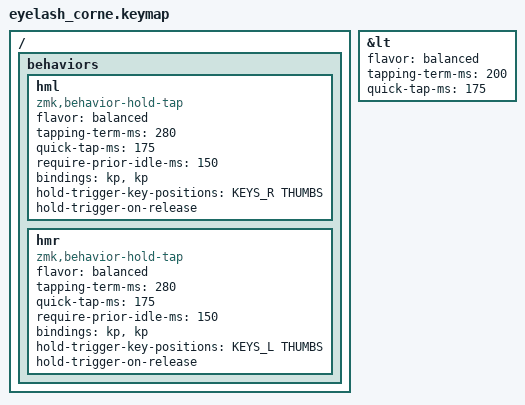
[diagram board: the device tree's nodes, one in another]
#include <behaviors.dtsi>
#include <dt-bindings/zmk/keys.h>

#include <dt-bindings/zmk/bt.h>
#include <dt-bindings/zmk/outputs.h>
#include <dt-bindings/zmk/ext_power.h>
#include <dt-bindings/zmk/rgb.h>

#include "zmk-helpers/helper.h"
#include "zmk-helpers/key-labels/eyelash42.h"

#include "mouse.dtsi"

// This keyboard layout is losely based on Miryoku.
// Todo:
// - [x] correct the number layer to include all numbers.
// - [x] add meny key.
// - [ ] correct navigation layer to put navigation symbols to right hand.
// - [ ] put the mouse navigation to joystick.
// - [ ] add the layers to configure bluetooth connections.


#define ZMK_BASE_LAYER(name, LT, RT, LM, RM, LB, RB, LH, RH, LS0, LS13, LS4, sensors)                   \
    ZMK_LAYER(                                                                 \
        name,                                                                  \
                 LT     LS0     RT                  \
                 LM     LS13    RM                  \
                 LB     LS4     RB                  \
                 LH             RH                  \
    ,sensors)


#define _BT_SEL_KEYS_                                                        \
    &bt BT_SEL 0 &bt BT_SEL 1 &bt BT_SEL 2 &bt BT_SEL 3 &bt BT_CLR

#define DEF 0
#define FN  1
#define NAV 2
#define SYM 3
#define CFG 4

#define XXX &none
#define ___ &trans

/* Global defaults */

/* Homerow mods */

#define KEYS_L LT0 LT1 LT2 LT3 LT4 LM0 LM1 LM2 LM3 LM4 LB0 LB1 LB2 LB3 LB4
#define KEYS_R RT0 RT1 RT2 RT3 RT4 RM0 RM1 RM2 RM3 RM4 RB0 RB1 RB2 RB3 RB4

#define THUMBS LH2 LH1 LH0 RH0 RH1 RH2 // Thumbs on 36+ keys.

#define U_COPY RC(INS)
#define U_PASTE RS(INS)
#define U_CUT RS(DEL)

#define U_UNDO RC(Z)
#define U_REDO LC(LA(Z))

#define U_TILDE RS(GRAVE)

&lt {
  flavor = "balanced";
  tapping-term-ms = <200>;
  quick-tap-ms = <175>;
};

/* Left-hand HRMs. */
ZMK_HOLD_TAP(hml,
    flavor = "balanced";
    tapping-term-ms = <280>;
    quick-tap-ms = <175>;
    require-prior-idle-ms = <150>;
    bindings = <&kp>, <&kp>;
    hold-trigger-key-positions = <KEYS_R THUMBS>;
    hold-trigger-on-release;
)

/* Right-hand HRMs. */
ZMK_HOLD_TAP(hmr,
    flavor = "balanced";
    tapping-term-ms = <280>;
    quick-tap-ms = <175>;
    require-prior-idle-ms = <150>;
    bindings = <&kp>, <&kp>;
    hold-trigger-key-positions = <KEYS_L THUMBS>;
    hold-trigger-on-release;
)


/* Keymap */

#define kBKSLASH NON_US_BACKSLASH


ZMK_BASE_LAYER(Qwerty,
// ╭───────────────┬───────────────┬───────────────┬───────────────┬───────────────┬───────────────╮          ╭───────────────┬───────────────┬───────────────┬───────────────┬───────────────┬───────────────╮
    &lt 4 GRAVE     &kp Q           &kp W           &kp E            &kp R          &kp T          ,           &kp Y           &kp U           &kp I           &kp O           &kp P           &lt 4 LEFT_BRACKET,
// ├───────────────┼───────────────┼───────────────┼───────────────┼───────────────┼───────────────┤          ├───────────────┼───────────────┼───────────────┼───────────────┼───────────────┼───────────────┤
    &kp kBKSLASH    &hml LGUI A     &hml LALT S     &hml LCTRL D    &hml LSHFT F   &kp G           ,           &kp H           &hmr RSHFT J    &hmr RCTRL K    &hmr LALT L     &hmr RGUI SEMI  &kp RIGHT_BRACKET,
// ├───────────────┼───────────────┼───────────────┼───────────────┼───────────────┼───────────────┤          ├───────────────┼───────────────┼───────────────┼───────────────┼───────────────┼───────────────┤
    &kp MINUS       &kp Z           &kp X           &kp C           &kp V           &kp B          ,           &kp N           &kp M           &kp COMMA       &kp DOT         &kp FSLH        &kp SQT        ,
// ╰───────────────┴───────────────┴───────────────┼───────────────┼───────────────┼───────────────┤          ├───────────────┼───────────────┼───────────────┼───────────────┴───────────────┴───────────────╯
                                                    &lt 1 ESCAPE    &lt 2 SPACE     &lt 3 TAB      ,           &lt 3 ENTER     &lt 2 BACKSPACE &lt 1  DELETE  ,
//                                                 ╰───────────────┴───────────────┴───────────────╯          ╰───────────────┴───────────────┴───────────────╯
// ╭───────────────┬───────────────┬───────────────╮
                     &kp UP                        ,
// ├───────────────┼───────────────┼───────────────┤
    &kp LEFT         &kp ENTER         &kp RIGHT   ,
// ├───────────────┼───────────────┼───────────────┤
    &kp C_MUTE       &kp DOWN                      ,
// ╰───────────────┴───────────────┴───────────────╯
&inc_dec_kp C_VOLUME_UP C_VOLUME_DOWN
)

ZMK_BASE_LAYER(Funnum,
// ╭───────────────┬───────────────┬───────────────┬───────────────┬───────────────┬───────────────╮          ╭───────────────┬───────────────┬───────────────┬───────────────┬───────────────┬───────────────╮
    XXX             &kp F9          &kp F10         &kp F11         &kp F12         &kp KP_MULTIPLY,           &kp PLUS        &kp N7          &kp N8          &kp N9          &kp N0          XXX            ,
// ├───────────────┼───────────────┼───────────────┼───────────────┼───────────────┼───────────────┤          ├───────────────┼───────────────┼───────────────┼───────────────┼───────────────┼───────────────┤
    XXX             &hml LGUI F5    &hml LALT F6    &hml LCTRL F7   &hml LSHFT F8   &kp KP_DIVIDE  ,           &kp MINUS       &hmr RSHFT N4   &hmr RCTRL N5   &hmr LALT N6    &kp  LGUI       XXX            ,
// ├───────────────┼───────────────┼───────────────┼───────────────┼───────────────┼───────────────┤          ├───────────────┼───────────────┼───────────────┼───────────────┼───────────────┼───────────────┤
    XXX             &kp F1          &kp F2          &kp F3          &kp F4          &kp kBKSLASH   ,           &kp EQUAL    &kp N1          &kp N2          &kp N3             XXX             XXX            ,
// ╰───────────────┴───────────────┴───────────────┼───────────────┼───────────────┼───────────────┤          ├───────────────┼───────────────┼───────────────┼───────────────┴───────────────┴───────────────╯
                                                    ___             ___             ___            ,           ___             ___             ___            ,
//                                                 ╰───────────────┴───────────────┴───────────────╯          ╰───────────────┴───────────────┴───────────────╯
// ╭───────────────┬───────────────┬───────────────╮
                     &kp UP                        ,
// ├───────────────┼───────────────┼───────────────┤
    &kp LEFT         &kp ENTER         &kp RIGHT   ,
// ├───────────────┼───────────────┼───────────────┤
    &kp B            &kp DOWN                      ,
// ╰───────────────┴───────────────┴───────────────╯
&inc_dec_kp C_VOLUME_UP C_VOLUME_DOWN
)

ZMK_BASE_LAYER(Nav,
// ╭───────────────┬───────────────┬───────────────┬───────────────┬───────────────┬───────────────╮          ╭───────────────┬───────────────┬───────────────┬───────────────┬───────────────┬───────────────╮
    XXX             &kp CAPS        &mkp LCLK       &mkp MCLK       &mkp RCLK       U_WH_U         ,           &kp PG_UP       &kp HOME        &kp UP          &kp END         &kp PSCRN       XXX            ,
// ├───────────────┼───────────────┼───────────────┼───────────────┼───────────────┼───────────────┤          ├───────────────┼───────────────┼───────────────┼───────────────┼───────────────┼───────────────┤
    XXX             &kp LGUI        &kp LALT        &kp LCTRL       &kp RSHFT       U_WH_D         ,           &kp PG_DN       &kp LEFT        &kp DOWN        &kp RIGHT       &kp PAUSE_BREAK XXX            ,
// ├───────────────┼───────────────┼───────────────┼───────────────┼───────────────┼───────────────┤          ├───────────────┼───────────────┼───────────────┼───────────────┼───────────────┼───────────────┤
    XXX             &kp U_UNDO      &kp U_CUT       &kp U_COPY      &kp U_PASTE     &kp K_APP      ,           &kp INS         XXX             XXX             XXX             XXX             XXX            ,
// ╰───────────────┴───────────────┴───────────────┼───────────────┼───────────────┼───────────────┤          ├───────────────┼───────────────┼───────────────┼───────────────┴───────────────┴───────────────╯
                                                    ___             ___             ___            ,           ___             ___             ___            ,
//                                                 ╰───────────────┴───────────────┴───────────────╯          ╰───────────────┴───────────────┴───────────────╯

// ╭───────────────┬───────────────┬───────────────╮
                    U_MS_U                         ,
// ├───────────────┼───────────────┼───────────────┤
    U_MS_L          &mkp LCLK       U_MS_R         ,
// ├───────────────┼───────────────┼───────────────┤
    &mkp RCLK       U_MS_D                         ,
// ╰───────────────┴───────────────┴───────────────╯
&inc_dec_kp C_VOLUME_UP C_VOLUME_DOWN
)

ZMK_BASE_LAYER(Symbol,
// ╭───────────────┬───────────────┬───────────────┬───────────────┬───────────────┬───────────────╮          ╭───────────────┬───────────────┬───────────────┬───────────────┬───────────────┬───────────────╮
    XXX             &kp LESS_THAN   &kp EXCL        &kp KP_MINUS    &kp GREATER_THAN &kp AMPERSAND ,           &kp CARET       &kp LEFT_BRACE  &kp RIGHT_BRACE &kp DOLLAR      &kp UNDERSCORE  XXX            ,
// ├───────────────┼───────────────┼───────────────┼───────────────┼───────────────┼───────────────┤          ├───────────────┼───────────────┼───────────────┼───────────────┼───────────────┼───────────────┤
    XXX             &hml LGUI LBKT  &hml LALT RBKT  &hml LCTRL KP_PLUS &hml LSHFT  EQUAL  &kp PIPE ,           &kp HASH        &hmr RSHFT LPAR &hmr RCTRL RPAR &hmr LALT SEMI  &hmr RGUI DOUBLE_QUOTES XXX    ,
// ├───────────────┼───────────────┼───────────────┼───────────────┼───────────────┼───────────────┤          ├───────────────┼───────────────┼───────────────┼───────────────┼───────────────┼───────────────┤
    XXX             &kp GRAVE       &kp TILDE       &kp KP_MULTIPLY &kp KP_DIVIDE   &kp PERCENT    ,           &kp AT          &kp COLON       &kp COMMA       &kp DOT         &kp APOSTROPHE  XXX            ,
// ╰───────────────┴───────────────┴───────────────┼───────────────┼───────────────┼───────────────┤          ├───────────────┼───────────────┼───────────────┼───────────────┴───────────────┴───────────────╯
                                                    ___             ___             ___            ,           ___             ___             ___            ,
//                                                 ╰───────────────┴───────────────┴───────────────╯          ╰───────────────┴───────────────┴───────────────╯

// ╭───────────────┬───────────────┬───────────────╮
                     &kp UP                        ,
// ├───────────────┼───────────────┼───────────────┤
    &kp LEFT         &kp ENTER      &kp RIGHT      ,
// ├───────────────┼───────────────┼───────────────┤
    &kp D            &kp DOWN                      ,
// ╰───────────────┴───────────────┴───────────────╯
&inc_dec_kp C_VOLUME_UP C_VOLUME_DOWN
)


ZMK_BASE_LAYER(Config,
// ╭───────────────┬───────────────┬───────────────┬───────────────┬───────────────┬───────────────╮          ╭───────────────┬───────────────┬───────────────┬───────────────┬───────────────┬───────────────╮
    ___             &bt BT_SEL 0    &bt BT_SEL 1    &bt BT_SEL 2    &bt BT_SEL 3    &bt BT_SEL 4   ,           &rgb_ug RGB_EFR ___             ___             ___             ___             ___            ,
// ├───────────────┼───────────────┼───────────────┼───────────────┼───────────────┼───────────────┤          ├───────────────┼───────────────┼───────────────┼───────────────┼───────────────┼───────────────┤
    ___             ___             ___             ___             ___             &out OUT_BLE   ,           &rgb_ug RGB_EFF ___             ___             ___             ___             ___            ,
// ├───────────────┼───────────────┼───────────────┼───────────────┼───────────────┼───────────────┤          ├───────────────┼───────────────┼───────────────┼───────────────┼───────────────┼───────────────┤
    ___             ___             ___             ___             ___             &out OUT_USB            ,           ___             ___             ___             ___             ___             ___            ,
// ╰───────────────┴───────────────┴───────────────┼───────────────┼───────────────┼───────────────┤          ├───────────────┼───────────────┼───────────────┼───────────────┴───────────────┴───────────────╯
                                                    ___             ___             ___            ,           ___             ___             ___            ,
//                                                 ╰───────────────┴───────────────┴───────────────╯          ╰───────────────┴───────────────┴───────────────╯
// ╭───────────────┬───────────────┬───────────────╮
                    &rgb_ug RGB_BRI                ,
// ├───────────────┼───────────────┼───────────────┤
    &rgb_ug RGB_HUD &rgb_ug RGB_TOG &rgb_ug RGB_HUI,
// ├───────────────┼───────────────┼───────────────┤
    &bt BT_CLR      &rgb_ug RGB_BRD                ,
// ╰───────────────┴───────────────┴───────────────╯
&inc_dec_kp C_VOLUME_UP C_VOLUME_DOWN
)

/*
ZMK_BASE_LAYER(Dummy,
// ╭───────────────┬───────────────┬───────────────┬───────────────┬───────────────┬───────────────╮          ╭───────────────┬───────────────┬───────────────┬───────────────┬───────────────┬───────────────╮
    ___             ___             ___             ___             ___             ___            ,           ___             ___             ___             ___             ___             ___            ,
// ├───────────────┼───────────────┼───────────────┼───────────────┼───────────────┼───────────────┤          ├───────────────┼───────────────┼───────────────┼───────────────┼───────────────┼───────────────┤
    ___             ___             ___             ___             ___             ___            ,           ___             ___             ___             ___             ___             ___            ,
// ├───────────────┼───────────────┼───────────────┼───────────────┼───────────────┼───────────────┤          ├───────────────┼───────────────┼───────────────┼───────────────┼───────────────┼───────────────┤
    ___             ___             ___             ___             ___             ___            ,           ___             ___             ___             ___             ___             ___            ,
// ╰───────────────┴───────────────┴───────────────┼───────────────┼───────────────┼───────────────┤          ├───────────────┼───────────────┼───────────────┼───────────────┴───────────────┴───────────────╯
                                                    ___             ___             ___            ,           ___             ___             ___            ,
//                                                 ╰───────────────┴───────────────┴───────────────╯          ╰───────────────┴───────────────┴───────────────╯
// ╭───────────────┬───────────────┬───────────────╮
                     &kp UP                        ,
// ├───────────────┼───────────────┼───────────────┤
    &kp LEFT         &kp ENTER         &kp RIGHT   ,
// ├───────────────┼───────────────┼───────────────┤
                     &kp DOWN                      ,
// ╰───────────────┴───────────────┴───────────────╯
&inc_dec_kp C_VOLUME_UP C_VOLUME_DOWN
)
*/

/* vim: set ft=c tw=146: */

// /{ chosen { zmk,physical-layout = &default_layout; }; };
